# AT32F415xx register map
Vendor: Keil; Series: AT32F415; File version: 1.0
CPU: CM4 r0p1, little endian, no MPU, FPU, 4 interrupt priority bits
Registers are 32-bit, read-write, reset 0x0 unless marked. A register's access mark holds for its fields unless they carry their own. Offsets are from the block's base; [hi:lo] are bit positions; {n}, {i} and the like mark numbered series.

## USB_OTG_DEVICE — USB on the go full speed
Base 0x50000800
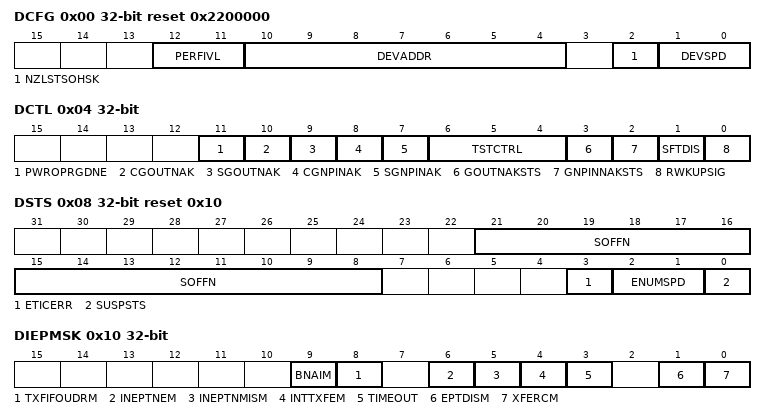
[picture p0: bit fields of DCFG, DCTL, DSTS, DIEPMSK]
0x00 DCFG reset 0x2200000 — OTG_FS device configuration register (OTG_FS_DCFG)
  [12:11] PERFIVL — Periodic frame interval
  [10:4] DEVADDR — Device address
  [2] NZLSTSOHSK — Non-zero-length status OUT handshake
  [1:0] DEVSPD — Device speed
0x04 DCTL — OTG_FS device control register (OTG_FS_DCTL)
  [11] PWROPRGDNE — Power-on programming done
  [10] CGOUTNAK — Clear global OUT NAK
  [9] SGOUTNAK — Set global OUT NAK
  [8] CGNPINAK — Clear global IN NAK
  [7] SGNPINAK — Set global IN NAK
  [6:4] TSTCTRL — Test control
  [3] GOUTNAKSTS ro — Global OUT NAK status
  [2] GNPINNAKSTS ro — Global IN NAK status
  [1] SFTDIS — Soft disconnect
  [0] RWKUPSIG — Remote wakeup signaling
0x08 DSTS ro reset 0x10 — OTG_FS device status register (OTG_FS_DSTS)
  [21:8] SOFFN — Frame number of the received SOF
  [3] ETICERR — Erratic error
  [2:1] ENUMSPD — Enumerated speed
  [0] SUSPSTS — Suspend status
0x10 DIEPMSK — OTG_FS device IN endpoint common interrupt mask register (OTG_FS_DIEPMSK)
  [9] BNAIM — BNA interrupt mask
  [8] TXFIFOUDRM — FIFO underrun mask
  [6] INEPTNEM — IN endpoint NAK effective mask
  [5] INEPTNMISM — IN token received with EP mismatch mask
  [4] INTTXFEM — IN token received when TxFIFO empty mask
  [3] TIMEOUT — Timeout condition mask (Non-isochronous endpoints)
  [1] EPTDISM — Endpoint disabled interrupt mask
  [0] XFERCM — Transfer completed interrupt mask
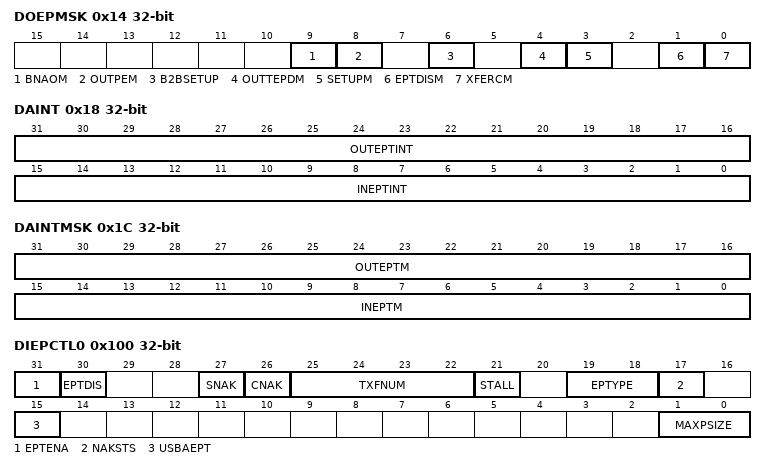
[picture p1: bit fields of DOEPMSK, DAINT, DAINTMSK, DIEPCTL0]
0x14 DOEPMSK — OTG_FS device OUT endpoint common interrupt mask register (OTG_FS_DOEPMSK)
  [9] BNAOM — BNA interrupt mask
  [8] OUTPEM — OUT packet error mask
  [6] B2BSETUP — Back-to-back SETUP packets received mask
  [4] OUTTEPDM — OUT token received when endpoint disabled mask
  [3] SETUPM — SETUP phase done mask
  [1] EPTDISM — Endpoint disabled interrupt mask
  [0] XFERCM — Transfer completed interrupt mask
0x18 DAINT ro — OTG_FS device all endpoints interrupt register (OTG_FS_DAINT)
  [31:16] OUTEPTINT — OUT endpoint interrupt bits
  [15:0] INEPTINT — IN endpoint interrupt bits
0x1C DAINTMSK — OTG_FS all endpoints interrupt mask register (OTG_FS_DAINTMSK)
  [31:16] OUTEPTM — OUT endpoint interrupt bits
  [15:0] INEPTM — IN EP interrupt mask bits
0x34 DIEPEMPMSK — OTG_FS device IN endpoint FIFO empty interrupt mask register
  [15:0] INEPTXFEM — IN EP Tx FIFO empty interrupt mask bits
0x100 DIEPCTL0 — OTG_FS device control IN endpoint 0 control register (OTG_FS_DIEPCTL0)
  [31] EPTENA ro — Endpoint enable
  [30] EPTDIS ro — Endpoint disable
  [27] SNAK wo — Set NAK
  [26] CNAK wo — Clear NAK
  [25:22] TXFNUM — TxFIFO number
  [21] STALL — STALL handshake
  [19:18] EPTYPE ro — Endpoint type
  [17] NAKSTS ro — NAK status
  [15] USBAEPT ro — USB active endpoint
  [1:0] MAXPSIZE — Maximum packet size
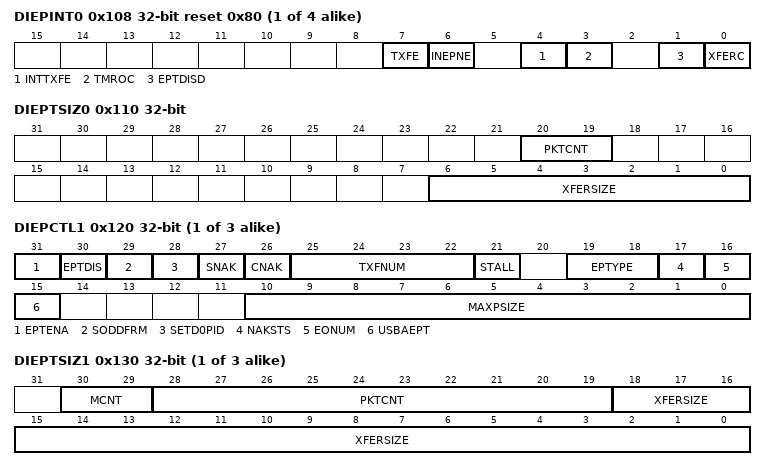
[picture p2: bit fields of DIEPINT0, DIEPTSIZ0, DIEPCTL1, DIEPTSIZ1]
{0x108+0x20*i} DIEPINT{i} reset 0x80 (i=0..3) — device endpoint-{i} interrupt register
  [7] TXFE ro — Transmit FIFO empty
  [6] INEPNE — IN endpoint NAK effective
  [4] INTTXFE — IN token received when TxFIFO is empty
  [3] TMROC — Timeout condition
  [1] EPTDISD — Endpoint disabled interrupt
  [0] XFERC — Transfer completed interrupt
0x110 DIEPTSIZ0 — device endpoint-0 transfer size register
  [20:19] PKTCNT — Packet count
  [6:0] XFERSIZE — Transfer size
{0x118+0x20*i} DTXFSTS{i} ro (i=0..3) — OTG_FS device IN endpoint transmit FIFO status register
  [15:0] INEPTFSAV — IN endpoint TxFIFO space available
{0x100+0x20*i} DIEPCTL{i} (i=1..3) — OTG device endpoint-{i} control register
  [31] EPTENA — Endpoint enable
  [30] EPTDIS — Endpoint disable
  [29] SODDFRM wo — Set odd frame
  [28] SETD0PID wo — Set DATA0 PID
  [27] SNAK wo — Set NAK
  [26] CNAK wo — Clear NAK
  [25:22] TXFNUM — TxFIFO number
  [21] STALL — STALL handshake
  [19:18] EPTYPE — Endpoint type
  [17] NAKSTS ro — NAK status
  [16] EONUM ro — Even/odd frame
  [15] USBAEPT — USB active endpoint
  [10:0] MAXPSIZE — Maximum packet size
{0x110+0x20*i} DIEPTSIZ{i} (i=1..3) — device endpoint-{i} transfer size register
  [30:29] MCNT — Multi count
  [28:19] PKTCNT — Packet count
  [18:0] XFERSIZE — Transfer size
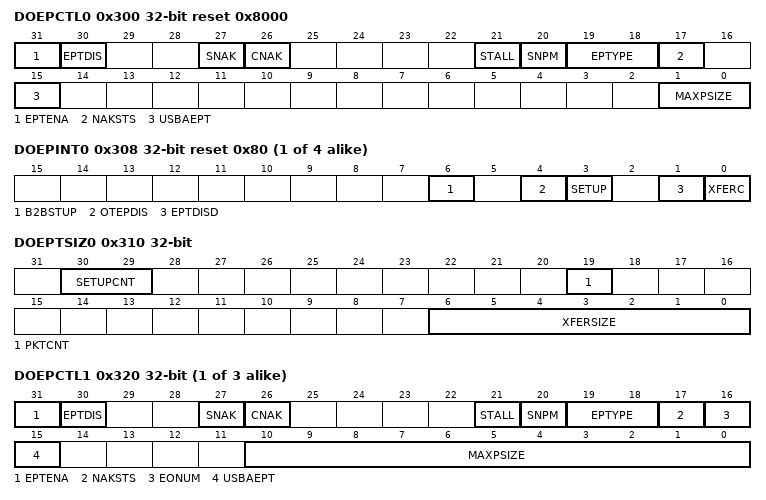
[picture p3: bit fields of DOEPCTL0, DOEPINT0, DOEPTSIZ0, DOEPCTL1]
0x300 DOEPCTL0 reset 0x8000 — device endpoint-0 control register
  [31] EPTENA wo — Endpoint enable
  [30] EPTDIS ro — Endpoint disable
  [27] SNAK wo — Set NAK
  [26] CNAK wo — Clear NAK
  [21] STALL — STALL handshake
  [20] SNPM — Snoop mode
  [19:18] EPTYPE ro — Endpoint type
  [17] NAKSTS ro — NAK status
  [15] USBAEPT ro — USB active endpoint
  [1:0] MAXPSIZE ro — Maximum packet size
{0x308+0x20*i} DOEPINT{i} reset 0x80 (i=0..3) — device endpoint-{i} interrupt register
  [6] B2BSTUP — Back-to-back SETUP packets received
  [4] OTEPDIS — OUT token received when endpoint disabled
  [3] SETUP — SETUP phase done
  [1] EPTDISD — Endpoint disabled interrupt
  [0] XFERC — Transfer completed interrupt
0x310 DOEPTSIZ0 — device OUT endpoint-0 transfer size register
  [30:29] SETUPCNT — SETUP packet count
  [19] PKTCNT — Packet count
  [6:0] XFERSIZE — Transfer size
{0x300+0x20*i} DOEPCTL{i} (i=1..3) — device endpoint-{i} control register
  [31] EPTENA wo — Endpoint enable
  [30] EPTDIS ro — Endpoint disable
  [27] SNAK wo — Set NAK
  [26] CNAK wo — Clear NAK
  [21] STALL — STALL handshake
  [20] SNPM — Snoop mode
  [19:18] EPTYPE ro — Endpoint type
  [17] NAKSTS ro — NAK status
  [16] EONUM ro — Even/odd frame
  [15] USBAEPT ro — USB active endpoint
  [10:0] MAXPSIZE — Maximum packet size
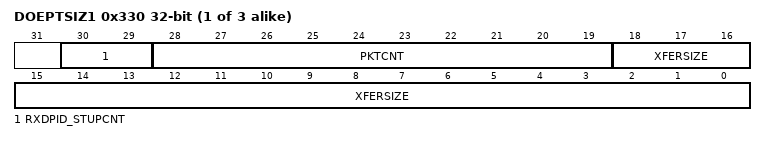
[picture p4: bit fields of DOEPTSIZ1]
{0x310+0x20*i} DOEPTSIZ{i} (i=1..3) — device OUT endpoint-{i} transfer size register
  [30:29] RXDPID_STUPCNT — Received data PID/SETUP packet count
  [28:19] PKTCNT — Packet count
  [18:0] XFERSIZE — Transfer size
